VERSION "created by canmatrix"

NS_ :

BS_: 250000

BU_:

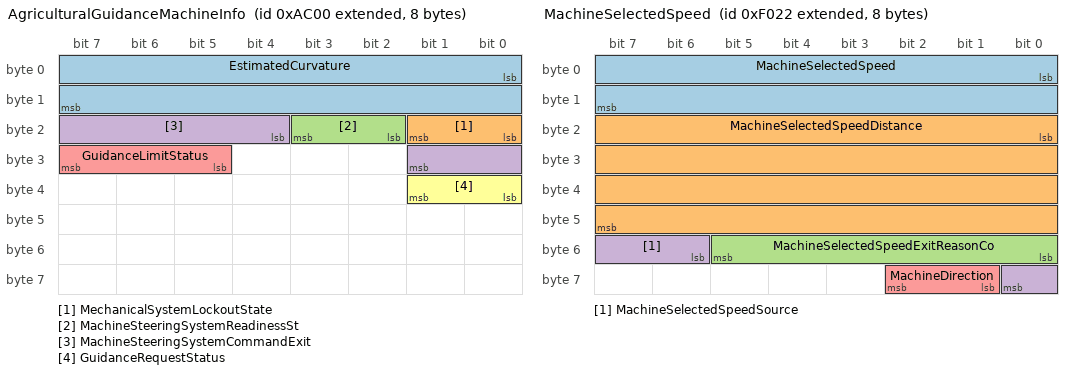
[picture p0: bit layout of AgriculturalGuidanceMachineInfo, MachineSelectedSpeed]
BO_ 2147527680 AgriculturalGuidanceMachineInfo: 8 Vector__XXX
 SG_ EstimatedCurvature : 0|16@1+ (0.25,-8032) [-8032.00|8351.75] "1/km" Vector__XXX
 SG_ MechanicalSystemLockoutState : 16|2@1+ (1,0) [0|3] "" Vector__XXX
 SG_ MachineSteeringSystemReadinessSt : 18|2@1+ (1,0) [0|3] "" Vector__XXX
 SG_ MachineSteeringSystemCommandExit : 20|6@1+ (1,0) [0|63] "" Vector__XXX
 SG_ GuidanceLimitStatus : 29|3@1+ (1,0) [0|7] "" Vector__XXX
 SG_ GuidanceRequestStatus : 32|2@1+ (1,0) [0|3] "" Vector__XXX

BO_ 2147527936 AgriculturalGuidanceSystemComman: 8 Vector__XXX
 SG_ CurvatureCommand : 0|16@1+ (0.25,-8032) [-8032.00|8351.75] "1/km" Vector__XXX
 SG_ CurvatureCommandStatus : 16|2@1+ (1,0) [0|3] "" Vector__XXX

BO_ 2147533568 DiagnosticMessage22: 8 Vector__XXX
 SG_ DiagnosticMessage22_RawPayload : 0|64@1+ (1,0) [0|18446744073709551615] "" Vector__XXX

BO_ 2147534592 ExtendedTransportProtocolDataTra: 8 Vector__XXX
 SG_ ExtendedTransportProtocolDataTra : 0|64@1+ (1,0) [0|18446744073709551615] "" Vector__XXX

BO_ 2147534848 ExtendedTransportProtocolConnect: 8 Vector__XXX
 SG_ ExtendedTransportProtocolConnect : 0|64@1+ (1,0) [0|18446744073709551615] "" Vector__XXX

BO_ 2147535616 ProcessData: 8 Vector__XXX
 SG_ ProcessData_RawPayload : 0|64@1+ (1,0) [0|18446744073709551615] "" Vector__XXX

BO_ 2147535872 RequestForRepetitionRate: 8 Vector__XXX
 SG_ RequestForRepetitionRate_RawPayl : 0|64@1+ (1,0) [0|18446744073709551615] "" Vector__XXX

BO_ 2147540736 DiagnosticMessage13: 8 Vector__XXX
 SG_ DiagnosticMessage13_RawPayload : 0|64@1+ (1,0) [0|18446744073709551615] "" Vector__XXX

BO_ 2147542528 VirtualTerminalToECU: 8 Vector__XXX
 SG_ VirtualTerminalToECU_RawPayload : 0|64@1+ (1,0) [0|18446744073709551615] "" Vector__XXX

BO_ 2147542784 ECUtoVirtualTerminal: 8 Vector__XXX
 SG_ ECUtoVirtualTerminal_RawPayload : 0|64@1+ (1,0) [0|18446744073709551615] "" Vector__XXX

BO_ 2147543040 Acknowledge: 8 Vector__XXX
 SG_ Acknowledge_RawPayload : 0|64@1+ (1,0) [0|18446744073709551615] "" Vector__XXX

BO_ 2147543552 ParameterGroupNumberRequest: 8 Vector__XXX
 SG_ ParameterGroupNumberRequest_RawP : 0|64@1+ (1,0) [0|18446744073709551615] "" Vector__XXX

BO_ 2147543808 TransportProtocolDataTransfer: 8 Vector__XXX
 SG_ TransportProtocolDataTransfer_Ra : 0|64@1+ (1,0) [0|18446744073709551615] "" Vector__XXX

BO_ 2147544064 TransportProtocolConnectionManag: 8 Vector__XXX
 SG_ TransportProtocolConnectionManag : 0|64@1+ (1,0) [0|18446744073709551615] "" Vector__XXX

BO_ 2147544576 AddressClaim: 8 Vector__XXX
 SG_ AddressClaim_RawPayload : 0|64@1+ (1,0) [0|18446744073709551615] "" Vector__XXX

BO_ 2147545122 MachineSelectedSpeed: 8 Vector__XXX
 SG_ MachineSelectedSpeed : 0|16@1+ (0.001000000000000000020816681711721685132943093776702880859375,0) [0E-060|65.53500000000000136422123598] "m/s" Vector__XXX
 SG_ MachineSelectedSpeedDistance : 16|32@1+ (1,0) [0|4294967295] "m" Vector__XXX
 SG_ MachineSelectedSpeedExitReasonCo : 48|6@1+ (1,0) [0|63] "" Vector__XXX
 SG_ MachineSelectedSpeedSource : 54|3@1+ (1,0) [0|7] "" Vector__XXX
 SG_ MachineDirection : 57|2@1+ (1,0) [0|3] "" Vector__XXX

BO_ 2147545316 HeartbeatMessage: 8 Vector__XXX
 SG_ HeartbeatSequenceCounter : 0|8@1+ (1,0) [0|255] "" Vector__XXX

BO_ 2147548301 ProductIdentification: 8 Vector__XXX
 SG_ ProductIdentification_RawPayload : 0|64@1+ (1,0) [0|18446744073709551615] "" Vector__XXX

BO_ 2147548302 ControlFunctionFunctionalities: 8 Vector__XXX
 SG_ ControlFunctionFunctionalities_R : 0|64@1+ (1,0) [0|18446744073709551615] "" Vector__XXX

BO_ 2147548466 DiagnosticProtocolIdentification: 8 Vector__XXX
 SG_ DiagnosticProtocolIdentification : 0|64@1+ (1,0) [0|18446744073709551615] "" Vector__XXX

BO_ 2147548483 MachineSelectedSpeedCommand: 8 Vector__XXX
 SG_ MachineSelectedSpeedCommand_RawP : 0|64@1+ (1,0) [0|18446744073709551615] "" Vector__XXX

BO_ 2147548685 WorkingSetMaster: 8 Vector__XXX
 SG_ WorkingSetMaster_RawPayload : 0|64@1+ (1,0) [0|18446744073709551615] "" Vector__XXX

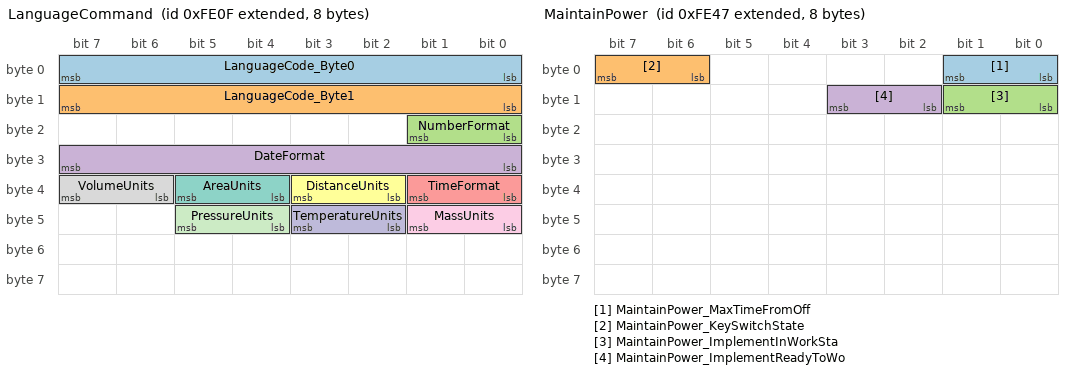
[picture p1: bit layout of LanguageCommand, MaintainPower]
BO_ 2147548687 LanguageCommand: 8 Vector__XXX
 SG_ LanguageCode_Byte0 : 0|8@1+ (1,0) [0|255] "" Vector__XXX
 SG_ LanguageCode_Byte1 : 8|8@1+ (1,0) [0|255] "" Vector__XXX
 SG_ NumberFormat : 16|2@1+ (1,0) [0|3] "" Vector__XXX
 SG_ DateFormat : 24|8@1+ (1,0) [0|255] "" Vector__XXX
 SG_ TimeFormat : 32|2@1+ (1,0) [0|3] "" Vector__XXX
 SG_ DistanceUnits : 34|2@1+ (1,0) [0|3] "" Vector__XXX
 SG_ AreaUnits : 36|2@1+ (1,0) [0|3] "" Vector__XXX
 SG_ VolumeUnits : 38|2@1+ (1,0) [0|3] "" Vector__XXX
 SG_ MassUnits : 40|2@1+ (1,0) [0|3] "" Vector__XXX
 SG_ TemperatureUnits : 42|2@1+ (1,0) [0|3] "" Vector__XXX
 SG_ PressureUnits : 44|2@1+ (1,0) [0|3] "" Vector__XXX

BO_ 2147548743 MaintainPower: 8 Vector__XXX
 SG_ MaintainPower_MaxTimeFromOff : 0|2@1+ (1,0) [0|3] "" Vector__XXX
 SG_ MaintainPower_KeySwitchState : 6|2@1+ (1,0) [0|3] "" Vector__XXX
 SG_ MaintainPower_ImplementInWorkSta : 8|2@1+ (1,0) [0|3] "" Vector__XXX
 SG_ MaintainPower_ImplementReadyToWo : 10|2@1+ (1,0) [0|3] "" Vector__XXX

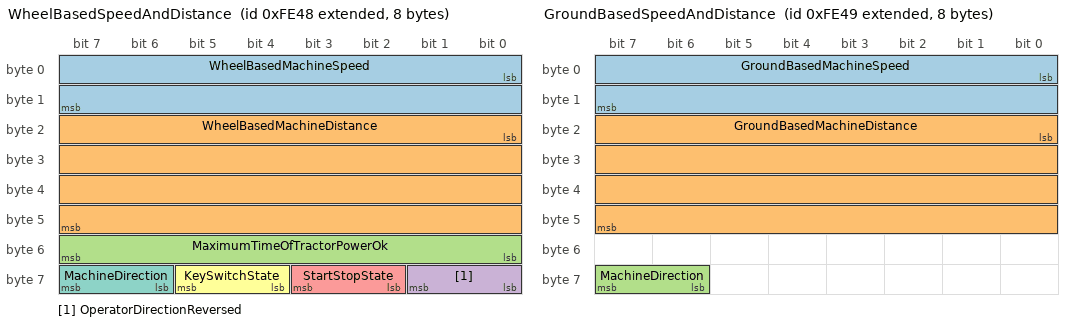
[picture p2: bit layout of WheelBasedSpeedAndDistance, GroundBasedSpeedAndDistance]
BO_ 2147548744 WheelBasedSpeedAndDistance: 8 Vector__XXX
 SG_ WheelBasedMachineSpeed : 0|16@1+ (0.001000000000000000020816681711721685132943093776702880859375,0) [0E-060|65.53500000000000136422123598] "m/s" Vector__XXX
 SG_ WheelBasedMachineDistance : 16|32@1+ (1,0) [0|4294967295] "m" Vector__XXX
 SG_ MaximumTimeOfTractorPowerOk : 48|8@1+ (1,0) [0|255] "minutes" Vector__XXX
 SG_ OperatorDirectionReversed : 56|2@1+ (1,0) [0|3] "" Vector__XXX
 SG_ StartStopState : 58|2@1+ (1,0) [0|3] "" Vector__XXX
 SG_ KeySwitchState : 60|2@1+ (1,0) [0|3] "" Vector__XXX
 SG_ MachineDirection : 62|2@1+ (1,0) [0|3] "" Vector__XXX

BO_ 2147548745 GroundBasedSpeedAndDistance: 8 Vector__XXX
 SG_ GroundBasedMachineSpeed : 0|16@1+ (0.001000000000000000020816681711721685132943093776702880859375,0) [0E-060|65.53500000000000136422123598] "m/s" Vector__XXX
 SG_ GroundBasedMachineDistance : 16|32@1+ (1,0) [0|4294967295] "m" Vector__XXX
 SG_ MachineDirection : 62|2@1+ (1,0) [0|3] "" Vector__XXX

BO_ 2147548613 ECUIdentificationInformation: 8 Vector__XXX
 SG_ ECUIdentificationInformation_Raw : 0|64@1+ (1,0) [0|18446744073709551615] "" Vector__XXX

BO_ 2147548874 DiagnosticMessage1: 8 Vector__XXX
 SG_ DiagnosticMessage1_RawPayload : 0|64@1+ (1,0) [0|18446744073709551615] "" Vector__XXX

BO_ 2147548875 DiagnosticMessage2: 8 Vector__XXX
 SG_ DiagnosticMessage2_RawPayload : 0|64@1+ (1,0) [0|18446744073709551615] "" Vector__XXX

BO_ 2147548876 DiagnosticMessage3: 8 Vector__XXX
 SG_ DiagnosticMessage3_RawPayload : 0|64@1+ (1,0) [0|18446744073709551615] "" Vector__XXX

BO_ 2147548883 DiagnosticMessage11: 8 Vector__XXX
 SG_ DiagnosticMessage11_RawPayload : 0|64@1+ (1,0) [0|18446744073709551615] "" Vector__XXX

BO_ 2147539200 DiagnosticMessage14: 8 Vector__XXX
 SG_ DiagnosticMessage14_RawPayload : 0|64@1+ (1,0) [0|18446744073709551615] "" Vector__XXX

BO_ 2147538944 DiagnosticMessage15: 8 Vector__XXX
 SG_ DiagnosticMessage15_RawPayload : 0|64@1+ (1,0) [0|18446744073709551615] "" Vector__XXX

BO_ 2147538688 DiagnosticMessage16: 8 Vector__XXX
 SG_ DiagnosticMessage16_RawPayload : 0|64@1+ (1,0) [0|18446744073709551615] "" Vector__XXX

BO_ 2147548888 CommandedAddress: 8 Vector__XXX
 SG_ CommandedAddress_RawPayload : 0|64@1+ (1,0) [0|18446744073709551615] "" Vector__XXX

BO_ 2147548890 SoftwareIdentification: 8 Vector__XXX
 SG_ SoftwareIdentification_RawPayloa : 0|64@1+ (1,0) [0|18446744073709551615] "" Vector__XXX

BO_ 2147548418 AllImplementsStopOperationsSwitc: 8 Vector__XXX
 SG_ AllImplementsStopOperationsSwitc : 0|64@1+ (1,0) [0|18446744073709551615] "" Vector__XXX

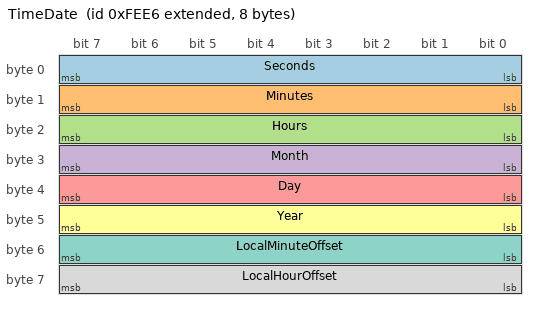
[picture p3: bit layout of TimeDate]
BO_ 2147548902 TimeDate: 8 Vector__XXX
 SG_ Seconds : 0|8@1+ (0.25,0) [0.00|63.75] "s" Vector__XXX
 SG_ Minutes : 8|8@1+ (1,0) [0|255] "min" Vector__XXX
 SG_ Hours : 16|8@1+ (1,0) [0|255] "h" Vector__XXX
 SG_ Month : 24|8@1+ (1,0) [0|255] "month" Vector__XXX
 SG_ Day : 32|8@1+ (0.25,0) [0.00|63.75] "day" Vector__XXX
 SG_ Year : 40|8@1+ (1,1985) [1985|2240] "year" Vector__XXX
 SG_ LocalMinuteOffset : 48|8@1+ (1,-125) [-125|130] "min" Vector__XXX
 SG_ LocalHourOffset : 56|8@1+ (1,-125) [-125|130] "h" Vector__XXX

BO_ 2147548907 ComponentIdentification: 8 Vector__XXX
 SG_ ComponentIdentification_RawPaylo : 0|64@1+ (1,0) [0|18446744073709551615] "" Vector__XXX

BO_ 2147610898 VesselHeading: 8 Vector__XXX
 SG_ VesselHeading_RawPayload : 0|64@1+ (1,0) [0|18446744073709551615] "" Vector__XXX

BO_ 2147610899 RateOfTurn: 8 Vector__XXX
 SG_ RateOfTurn_RawPayload : 0|64@1+ (1,0) [0|18446744073709551615] "" Vector__XXX

BO_ 2147612673 PositionRapidUpdate: 8 Vector__XXX
 SG_ PositionRapidUpdate_RawPayload : 0|64@1+ (1,0) [0|18446744073709551615] "" Vector__XXX

BO_ 2147612674 CourseOverGroundSpeedOverGroundR: 8 Vector__XXX
 SG_ CourseOverGroundSpeedOverGroundR : 0|64@1+ (1,0) [0|18446744073709551615] "" Vector__XXX

BO_ 2147612675 PositionDeltaHighPrecisionRapidU: 8 Vector__XXX
 SG_ PositionDeltaHighPrecisionRapidU : 0|64@1+ (1,0) [0|18446744073709551615] "" Vector__XXX

BO_ 2147612677 GNSSPositionData: 8 Vector__XXX
 SG_ GNSSPositionData_RawPayload : 0|64@1+ (1,0) [0|18446744073709551615] "" Vector__XXX

BO_ 2147612692 Datum: 8 Vector__XXX
 SG_ Datum_RawPayload : 0|64@1+ (1,0) [0|18446744073709551615] "" Vector__XXX

CM_ BO_ 2147527680  "Source: AgIsoStack++ can_general_parameter_group_numbers.hpp:19";
CM_ BO_ 2147527936  "Source: AgIsoStack++ can_general_parameter_group_numbers.hpp:20";
CM_ BO_ 2147533568  "Source: AgIsoStack++ can_general_parameter_group_numbers.hpp:21";
CM_ BO_ 2147534592  "Source: AgIsoStack++ can_general_parameter_group_numbers.hpp:22";
CM_ BO_ 2147534848  "Source: AgIsoStack++ can_general_parameter_group_numbers.hpp:23";
CM_ BO_ 2147535616  "Source: AgIsoStack++ can_general_parameter_group_numbers.hpp:24";
CM_ BO_ 2147535872  "Source: AgIsoStack++ can_general_parameter_group_numbers.hpp:25";
CM_ BO_ 2147540736  "Source: AgIsoStack++ can_general_parameter_group_numbers.hpp:26";
CM_ BO_ 2147542528  "Source: AgIsoStack++ can_general_parameter_group_numbers.hpp:27";
CM_ BO_ 2147542784  "Source: AgIsoStack++ can_general_parameter_group_numbers.hpp:28";
CM_ BO_ 2147543040  "Source: AgIsoStack++ can_general_parameter_group_numbers.hpp:29";
CM_ BO_ 2147543552  "Source: AgIsoStack++ can_general_parameter_group_numbers.hpp:30";
CM_ BO_ 2147543808  "Source: AgIsoStack++ can_general_parameter_group_numbers.hpp:31";
CM_ BO_ 2147544064  "Source: AgIsoStack++ can_general_parameter_group_numbers.hpp:32";
CM_ BO_ 2147544576  "Source: AgIsoStack++ can_general_parameter_group_numbers.hpp:33";
CM_ BO_ 2147545122  "Source: AgIsoStack++ can_general_parameter_group_numbers.hpp:35";
CM_ BO_ 2147545316  "Source: AgIsoStack++ can_general_parameter_group_numbers.hpp:36";
CM_ BO_ 2147548301  "Source: AgIsoStack++ can_general_parameter_group_numbers.hpp:37";
CM_ BO_ 2147548302  "Source: AgIsoStack++ can_general_parameter_group_numbers.hpp:38";
CM_ BO_ 2147548466  "Source: AgIsoStack++ can_general_parameter_group_numbers.hpp:39";
CM_ BO_ 2147548483  "Source: AgIsoStack++ can_general_parameter_group_numbers.hpp:40";
CM_ BO_ 2147548685  "Source: AgIsoStack++ can_general_parameter_group_numbers.hpp:41";
CM_ BO_ 2147548687  "Source: AgIsoStack++ can_general_parameter_group_numbers.hpp:42";
CM_ BO_ 2147548743  "Source: AgIsoStack++ can_general_parameter_group_numbers.hpp:43";
CM_ BO_ 2147548744  "Source: AgIsoStack++ can_general_parameter_group_numbers.hpp:44";
CM_ BO_ 2147548745  "Source: AgIsoStack++ can_general_parameter_group_numbers.hpp:45";
CM_ BO_ 2147548613  "Source: AgIsoStack++ can_general_parameter_group_numbers.hpp:46";
CM_ BO_ 2147548874  "Source: AgIsoStack++ can_general_parameter_group_numbers.hpp:47. DM1 carries Active Diagnostic Trouble Codes per SAE J1939-73. Payload layout (multi-DTC, variable length): byte 0 = lamp status (MIL / Red Stop / Amber Warning / Protect, 2 bits each); byte 1 = flash status for those 4 lamps; bytes 2+ = repeating 4-byte DTC records (SPN 19-bit + FMI 5-bit + OC 7-bit + CM 1-bit). Per-DTC decoding is reader-side; this DBC documents only the frame-level definition. Public reference: CSS Electronics J1939-73 explainer (csselectronics.com). Full decode contribution welcome — see CONTRIBUTING.md.";
CM_ BO_ 2147548875  "Source: AgIsoStack++ can_general_parameter_group_numbers.hpp:48";
CM_ BO_ 2147548876  "Source: AgIsoStack++ can_general_parameter_group_numbers.hpp:49";
CM_ BO_ 2147548883  "Source: AgIsoStack++ can_general_parameter_group_numbers.hpp:50";
CM_ BO_ 2147539200  "Source: AgIsoStack++ can_general_parameter_group_numbers.hpp:51";
CM_ BO_ 2147538944  "Source: AgIsoStack++ can_general_parameter_group_numbers.hpp:52";
CM_ BO_ 2147538688  "Source: AgIsoStack++ can_general_parameter_group_numbers.hpp:53";
CM_ BO_ 2147548888  "Source: AgIsoStack++ can_general_parameter_group_numbers.hpp:54";
CM_ BO_ 2147548890  "Source: AgIsoStack++ can_general_parameter_group_numbers.hpp:55";
CM_ BO_ 2147548418  "Source: AgIsoStack++ can_general_parameter_group_numbers.hpp:56";
CM_ BO_ 2147548902  "Source: AgIsoStack++ can_general_parameter_group_numbers.hpp:57";
CM_ BO_ 2147548907  "Source: AgIsoStack++ can_general_parameter_group_numbers.hpp:58";
CM_ BO_ 2147610898  "Source: AgIsoStack++ can_general_parameter_group_numbers.hpp:59 Note: this is an NMEA 2000 marine PGN. AgIsoStack++ reuses these for GNSS/heading because NMEA 2000 and ISO 11783 share the J1939 protocol layer; they are not part of ISO 11783-7 itself.";
CM_ BO_ 2147610899  "Source: AgIsoStack++ can_general_parameter_group_numbers.hpp:60 Note: this is an NMEA 2000 marine PGN. AgIsoStack++ reuses these for GNSS/heading because NMEA 2000 and ISO 11783 share the J1939 protocol layer; they are not part of ISO 11783-7 itself.";
CM_ BO_ 2147612673  "Source: AgIsoStack++ can_general_parameter_group_numbers.hpp:61 Note: this is an NMEA 2000 marine PGN. AgIsoStack++ reuses these for GNSS/heading because NMEA 2000 and ISO 11783 share the J1939 protocol layer; they are not part of ISO 11783-7 itself.";
CM_ BO_ 2147612674  "Source: AgIsoStack++ can_general_parameter_group_numbers.hpp:62";
CM_ BO_ 2147612675  "Source: AgIsoStack++ can_general_parameter_group_numbers.hpp:63";
CM_ BO_ 2147612677  "Source: AgIsoStack++ can_general_parameter_group_numbers.hpp:64 Note: this is an NMEA 2000 marine PGN. AgIsoStack++ reuses these for GNSS/heading because NMEA 2000 and ISO 11783 share the J1939 protocol layer; they are not part of ISO 11783-7 itself.";
CM_ BO_ 2147612692  "Source: AgIsoStack++ can_general_parameter_group_numbers.hpp:65 Note: this is an NMEA 2000 marine PGN. AgIsoStack++ reuses these for GNSS/heading because NMEA 2000 and ISO 11783 share the J1939 protocol layer; they are not part of ISO 11783-7 itself.";

CM_ SG_ 2147527680 EstimatedCurvature "Source: isobus_guidance_interface.hpp GuidanceMachineInfo";
CM_ SG_ 2147527680 MachineSteeringSystemCommandExit "Per ISO 11783-7 exit reason codes";
CM_ SG_ 2147527936 CurvatureCommand "Source: isobus_guidance_interface.hpp GuidanceSystemCommand";
CM_ SG_ 2147533568 DiagnosticMessage22_RawPayload "Generic 8-byte raw payload. Signal-level decoding requires ISO 11783-X spec lookup or AgIsoStack++ parser inspection  manual enrichment via PR welcome.";
CM_ SG_ 2147534592 ExtendedTransportProtocolDataTra "Generic 8-byte raw payload. Signal-level decoding requires ISO 11783-X spec lookup or AgIsoStack++ parser inspection  manual enrichment via PR welcome.";
CM_ SG_ 2147534848 ExtendedTransportProtocolConnect "Generic 8-byte raw payload. Signal-level decoding requires ISO 11783-X spec lookup or AgIsoStack++ parser inspection  manual enrichment via PR welcome.";
CM_ SG_ 2147535616 ProcessData_RawPayload "Generic 8-byte raw payload. Signal-level decoding requires ISO 11783-X spec lookup or AgIsoStack++ parser inspection  manual enrichment via PR welcome.";
CM_ SG_ 2147535872 RequestForRepetitionRate_RawPayl "Generic 8-byte raw payload. Signal-level decoding requires ISO 11783-X spec lookup or AgIsoStack++ parser inspection  manual enrichment via PR welcome.";
CM_ SG_ 2147540736 DiagnosticMessage13_RawPayload "Generic 8-byte raw payload. Signal-level decoding requires ISO 11783-X spec lookup or AgIsoStack++ parser inspection  manual enrichment via PR welcome.";
CM_ SG_ 2147542528 VirtualTerminalToECU_RawPayload "Generic 8-byte raw payload. Signal-level decoding requires ISO 11783-X spec lookup or AgIsoStack++ parser inspection  manual enrichment via PR welcome.";
CM_ SG_ 2147542784 ECUtoVirtualTerminal_RawPayload "Generic 8-byte raw payload. Signal-level decoding requires ISO 11783-X spec lookup or AgIsoStack++ parser inspection  manual enrichment via PR welcome.";
CM_ SG_ 2147543040 Acknowledge_RawPayload "Generic 8-byte raw payload. Signal-level decoding requires ISO 11783-X spec lookup or AgIsoStack++ parser inspection  manual enrichment via PR welcome.";
CM_ SG_ 2147543552 ParameterGroupNumberRequest_RawP "Generic 8-byte raw payload. Signal-level decoding requires ISO 11783-X spec lookup or AgIsoStack++ parser inspection  manual enrichment via PR welcome.";
CM_ SG_ 2147543808 TransportProtocolDataTransfer_Ra "Generic 8-byte raw payload. Signal-level decoding requires ISO 11783-X spec lookup or AgIsoStack++ parser inspection  manual enrichment via PR welcome.";
CM_ SG_ 2147544064 TransportProtocolConnectionManag "Generic 8-byte raw payload. Signal-level decoding requires ISO 11783-X spec lookup or AgIsoStack++ parser inspection  manual enrichment via PR welcome.";
CM_ SG_ 2147544576 AddressClaim_RawPayload "Generic 8-byte raw payload. Signal-level decoding requires ISO 11783-X spec lookup or AgIsoStack++ parser inspection  manual enrichment via PR welcome.";
CM_ SG_ 2147545122 MachineSelectedSpeed "Source: isobus_speed_distance_messages.hpp MachineSelectedSpeedData";
CM_ SG_ 2147545122 MachineSelectedSpeedExitReasonCo "Source-of-selected-speed exit reason code per ISO 11783-7";
CM_ SG_ 2147545122 MachineSelectedSpeedSource "0=Wheel 1=Ground 2=Navigation 3=Blended 4=Simulated";
CM_ SG_ 2147545316 HeartbeatSequenceCounter "Increments 0..250 then wraps; per isobus_heartbeat.hpp";
CM_ SG_ 2147548301 ProductIdentification_RawPayload "Generic 8-byte raw payload. Signal-level decoding requires ISO 11783-X spec lookup or AgIsoStack++ parser inspection  manual enrichment via PR welcome.";
CM_ SG_ 2147548302 ControlFunctionFunctionalities_R "Generic 8-byte raw payload. Signal-level decoding requires ISO 11783-X spec lookup or AgIsoStack++ parser inspection  manual enrichment via PR welcome.";
CM_ SG_ 2147548466 DiagnosticProtocolIdentification "Generic 8-byte raw payload. Signal-level decoding requires ISO 11783-X spec lookup or AgIsoStack++ parser inspection  manual enrichment via PR welcome.";
CM_ SG_ 2147548483 MachineSelectedSpeedCommand_RawP "Generic 8-byte raw payload. Signal-level decoding requires ISO 11783-X spec lookup or AgIsoStack++ parser inspection  manual enrichment via PR welcome.";
CM_ SG_ 2147548685 WorkingSetMaster_RawPayload "Generic 8-byte raw payload. Signal-level decoding requires ISO 11783-X spec lookup or AgIsoStack++ parser inspection  manual enrichment via PR welcome.";
CM_ SG_ 2147548687 LanguageCode_Byte0 "ASCII char 1 of ISO 639-1 language code, e.g. 'e' for en";
CM_ SG_ 2147548687 LanguageCode_Byte1 "ASCII char 2";
CM_ SG_ 2147548687 NumberFormat "Decimal separator + grouping convention";
CM_ SG_ 2147548687 DateFormat "0=ddmmyyyy 1=ddyyyymm 2=mmyyyydd 3=mmddyyyy 4=yyyymmdd 5=yyyyddmm";
CM_ SG_ 2147548687 TimeFormat "0=24h 1=12h";
CM_ SG_ 2147548687 DistanceUnits "0=metric 1=imperial-US 2=imperial-UK 3=reserved";
CM_ SG_ 2147548743 MaintainPower_MaxTimeFromOff "MaintainPower request  maximum time for ECU power-down";
CM_ SG_ 2147548744 WheelBasedMachineSpeed "Source: isobus_speed_distance_messages.hpp WheelBasedMachineSpeedData";
CM_ SG_ 2147548744 WheelBasedMachineDistance "Source: isobus_speed_distance_messages.hpp";
CM_ SG_ 2147548744 MaximumTimeOfTractorPowerOk "Source: isobus_speed_distance_messages.hpp";
CM_ SG_ 2147548744 OperatorDirectionReversed "0=NotReversed 1=Reversed 2=Error 3=NotAvailable";
CM_ SG_ 2147548744 StartStopState "0=Stop 1=Start 2=Error 3=NotAvailable";
CM_ SG_ 2147548744 KeySwitchState "0=Off 1=NotOff 2=Error 3=NotAvailable";
CM_ SG_ 2147548744 MachineDirection "0=Reverse 1=Forward 2=Error 3=NotAvailable";
CM_ SG_ 2147548745 GroundBasedMachineSpeed "Source: isobus_speed_distance_messages.hpp GroundBasedSpeedAndDistance";
CM_ SG_ 2147548745 GroundBasedMachineDistance "Source: isobus_speed_distance_messages.hpp";
CM_ SG_ 2147548745 MachineDirection "0=Reverse 1=Forward 2=Error 3=NotAvailable";
CM_ SG_ 2147548613 ECUIdentificationInformation_Raw "Generic 8-byte raw payload. Signal-level decoding requires ISO 11783-X spec lookup or AgIsoStack++ parser inspection  manual enrichment via PR welcome.";
CM_ SG_ 2147548874 DiagnosticMessage1_RawPayload "Generic 8-byte raw payload. Signal-level decoding requires ISO 11783-X spec lookup or AgIsoStack++ parser inspection  manual enrichment via PR welcome.";
CM_ SG_ 2147548875 DiagnosticMessage2_RawPayload "Generic 8-byte raw payload. Signal-level decoding requires ISO 11783-X spec lookup or AgIsoStack++ parser inspection  manual enrichment via PR welcome.";
CM_ SG_ 2147548876 DiagnosticMessage3_RawPayload "Generic 8-byte raw payload. Signal-level decoding requires ISO 11783-X spec lookup or AgIsoStack++ parser inspection  manual enrichment via PR welcome.";
CM_ SG_ 2147548883 DiagnosticMessage11_RawPayload "Generic 8-byte raw payload. Signal-level decoding requires ISO 11783-X spec lookup or AgIsoStack++ parser inspection  manual enrichment via PR welcome.";
CM_ SG_ 2147539200 DiagnosticMessage14_RawPayload "Generic 8-byte raw payload. Signal-level decoding requires ISO 11783-X spec lookup or AgIsoStack++ parser inspection  manual enrichment via PR welcome.";
CM_ SG_ 2147538944 DiagnosticMessage15_RawPayload "Generic 8-byte raw payload. Signal-level decoding requires ISO 11783-X spec lookup or AgIsoStack++ parser inspection  manual enrichment via PR welcome.";
CM_ SG_ 2147538688 DiagnosticMessage16_RawPayload "Generic 8-byte raw payload. Signal-level decoding requires ISO 11783-X spec lookup or AgIsoStack++ parser inspection  manual enrichment via PR welcome.";
CM_ SG_ 2147548888 CommandedAddress_RawPayload "Generic 8-byte raw payload. Signal-level decoding requires ISO 11783-X spec lookup or AgIsoStack++ parser inspection  manual enrichment via PR welcome.";
CM_ SG_ 2147548890 SoftwareIdentification_RawPayloa "Generic 8-byte raw payload. Signal-level decoding requires ISO 11783-X spec lookup or AgIsoStack++ parser inspection  manual enrichment via PR welcome.";
CM_ SG_ 2147548418 AllImplementsStopOperationsSwitc "Generic 8-byte raw payload. Signal-level decoding requires ISO 11783-X spec lookup or AgIsoStack++ parser inspection  manual enrichment via PR welcome.";
CM_ SG_ 2147548907 ComponentIdentification_RawPaylo "Generic 8-byte raw payload. Signal-level decoding requires ISO 11783-X spec lookup or AgIsoStack++ parser inspection  manual enrichment via PR welcome.";
CM_ SG_ 2147610898 VesselHeading_RawPayload "Generic 8-byte raw payload. Signal-level decoding requires ISO 11783-X spec lookup or AgIsoStack++ parser inspection  manual enrichment via PR welcome.";
CM_ SG_ 2147610899 RateOfTurn_RawPayload "Generic 8-byte raw payload. Signal-level decoding requires ISO 11783-X spec lookup or AgIsoStack++ parser inspection  manual enrichment via PR welcome.";
CM_ SG_ 2147612673 PositionRapidUpdate_RawPayload "Generic 8-byte raw payload. Signal-level decoding requires ISO 11783-X spec lookup or AgIsoStack++ parser inspection  manual enrichment via PR welcome.";
CM_ SG_ 2147612674 CourseOverGroundSpeedOverGroundR "Generic 8-byte raw payload. Signal-level decoding requires ISO 11783-X spec lookup or AgIsoStack++ parser inspection  manual enrichment via PR welcome.";
CM_ SG_ 2147612675 PositionDeltaHighPrecisionRapidU "Generic 8-byte raw payload. Signal-level decoding requires ISO 11783-X spec lookup or AgIsoStack++ parser inspection  manual enrichment via PR welcome.";
CM_ SG_ 2147612677 GNSSPositionData_RawPayload "Generic 8-byte raw payload. Signal-level decoding requires ISO 11783-X spec lookup or AgIsoStack++ parser inspection  manual enrichment via PR welcome.";
CM_ SG_ 2147612692 Datum_RawPayload "Generic 8-byte raw payload. Signal-level decoding requires ISO 11783-X spec lookup or AgIsoStack++ parser inspection  manual enrichment via PR welcome.";

BA_DEF_ BO_ "SystemMessageLongSymbol" STRING;
BA_DEF_ SG_ "GenSigStartValue" FLOAT 0 100000000000;
BA_DEF_ SG_ "SystemSignalLongSymbol" STRING;

BA_ "SystemMessageLongSymbol" BO_ 2147527936 "AgriculturalGuidanceSystemCommand";
BA_ "SystemMessageLongSymbol" BO_ 2147534592 "ExtendedTransportProtocolDataTransfer";
BA_ "SystemMessageLongSymbol" BO_ 2147534848 "ExtendedTransportProtocolConnectionManagement";
BA_ "SystemMessageLongSymbol" BO_ 2147544064 "TransportProtocolConnectionManagement";
BA_ "SystemMessageLongSymbol" BO_ 2147548418 "AllImplementsStopOperationsSwitchState";
BA_ "SystemMessageLongSymbol" BO_ 2147612674 "CourseOverGroundSpeedOverGroundRapidUpdate";
BA_ "SystemMessageLongSymbol" BO_ 2147612675 "PositionDeltaHighPrecisionRapidUpdate";

BA_ "GenSigStartValue" SG_ 2147527680 EstimatedCurvature 32128;
BA_ "SystemSignalLongSymbol" SG_ 2147527680 MachineSteeringSystemReadinessSt "MachineSteeringSystemReadinessState";
BA_ "SystemSignalLongSymbol" SG_ 2147527680 MachineSteeringSystemCommandExit "MachineSteeringSystemCommandExitReasonCode";
BA_ "GenSigStartValue" SG_ 2147527936 CurvatureCommand 32128;
BA_ "SystemSignalLongSymbol" SG_ 2147534592 ExtendedTransportProtocolDataTra "ExtendedTransportProtocolDataTransfer_RawPayload";
BA_ "SystemSignalLongSymbol" SG_ 2147534848 ExtendedTransportProtocolConnect "ExtendedTransportProtocolConnectionManagement_RawPayload";
BA_ "SystemSignalLongSymbol" SG_ 2147535872 RequestForRepetitionRate_RawPayl "RequestForRepetitionRate_RawPayload";
BA_ "SystemSignalLongSymbol" SG_ 2147543552 ParameterGroupNumberRequest_RawP "ParameterGroupNumberRequest_RawPayload";
BA_ "SystemSignalLongSymbol" SG_ 2147543808 TransportProtocolDataTransfer_Ra "TransportProtocolDataTransfer_RawPayload";
BA_ "SystemSignalLongSymbol" SG_ 2147544064 TransportProtocolConnectionManag "TransportProtocolConnectionManagement_RawPayload";
BA_ "SystemSignalLongSymbol" SG_ 2147545122 MachineSelectedSpeedExitReasonCo "MachineSelectedSpeedExitReasonCode";
BA_ "SystemSignalLongSymbol" SG_ 2147548302 ControlFunctionFunctionalities_R "ControlFunctionFunctionalities_RawPayload";
BA_ "SystemSignalLongSymbol" SG_ 2147548466 DiagnosticProtocolIdentification "DiagnosticProtocolIdentification_RawPayload";
BA_ "SystemSignalLongSymbol" SG_ 2147548483 MachineSelectedSpeedCommand_RawP "MachineSelectedSpeedCommand_RawPayload";
BA_ "SystemSignalLongSymbol" SG_ 2147548743 MaintainPower_ImplementInWorkSta "MaintainPower_ImplementInWorkState";
BA_ "SystemSignalLongSymbol" SG_ 2147548743 MaintainPower_ImplementReadyToWo "MaintainPower_ImplementReadyToWorkState";
BA_ "SystemSignalLongSymbol" SG_ 2147548613 ECUIdentificationInformation_Raw "ECUIdentificationInformation_RawPayload";
BA_ "SystemSignalLongSymbol" SG_ 2147548890 SoftwareIdentification_RawPayloa "SoftwareIdentification_RawPayload";
BA_ "SystemSignalLongSymbol" SG_ 2147548418 AllImplementsStopOperationsSwitc "AllImplementsStopOperationsSwitchState_RawPayload";
BA_ "GenSigStartValue" SG_ 2147548902 LocalMinuteOffset 125;
BA_ "GenSigStartValue" SG_ 2147548902 LocalHourOffset 125;
BA_ "SystemSignalLongSymbol" SG_ 2147548907 ComponentIdentification_RawPaylo "ComponentIdentification_RawPayload";
BA_ "SystemSignalLongSymbol" SG_ 2147612674 CourseOverGroundSpeedOverGroundR "CourseOverGroundSpeedOverGroundRapidUpdate_RawPayload";
BA_ "SystemSignalLongSymbol" SG_ 2147612675 PositionDeltaHighPrecisionRapidU "PositionDeltaHighPrecisionRapidUpdate_RawPayload";

VAL_ 2147527680 MechanicalSystemLockoutState 0 "NotActive" 1 "Active" 2 "Error" 3 "NotAvailable";
VAL_ 2147527680 MachineSteeringSystemReadinessSt 0 "NotReady" 1 "Ready" 2 "Error" 3 "NotAvailable";
VAL_ 2147527680 GuidanceLimitStatus 0 "NotLimited" 1 "OperatorLimited" 2 "LimitedHigh" 3 "LimitedLow";
VAL_ 2147527680 GuidanceRequestStatus 0 "RequiredNoSteer" 1 "Required" 2 "Error" 3 "NotAvailable";
VAL_ 2147527936 CurvatureCommandStatus 0 "IntendedNotSteering" 1 "IntendedSteering" 2 "Error" 3 "NotAvailable";
VAL_ 2147545122 MachineSelectedSpeedSource 0 "Wheel" 1 "Ground" 2 "Navigation" 3 "Blended" 4 "Simulated";
VAL_ 2147545122 MachineDirection 0 "Reverse" 1 "Forward" 2 "Error" 3 "NotAvailable";
VAL_ 2147548743 MaintainPower_MaxTimeFromOff 0 "DoNotMaintain" 1 "Maintain2Sec" 2 "MaintainExt" 3 "NotAvailable";
VAL_ 2147548743 MaintainPower_KeySwitchState 0 "Off" 1 "NotOff" 2 "Error" 3 "NotAvailable";
VAL_ 2147548743 MaintainPower_ImplementInWorkSta 0 "NotInWork" 1 "InWork" 2 "Error" 3 "NotAvailable";
VAL_ 2147548743 MaintainPower_ImplementReadyToWo 0 "NotReady" 1 "Ready" 2 "Error" 3 "NotAvailable";
VAL_ 2147548744 OperatorDirectionReversed 0 "NotReversed" 1 "Reversed" 2 "Error" 3 "NotAvailable";
VAL_ 2147548744 StartStopState 0 "Stop" 1 "Start" 2 "Error" 3 "NotAvailable";
VAL_ 2147548744 KeySwitchState 0 "Off" 1 "NotOff" 2 "Error" 3 "NotAvailable";
VAL_ 2147548744 MachineDirection 0 "Reverse" 1 "Forward" 2 "Error" 3 "NotAvailable";
VAL_ 2147548745 MachineDirection 0 "Reverse" 1 "Forward" 2 "Error" 3 "NotAvailable";
